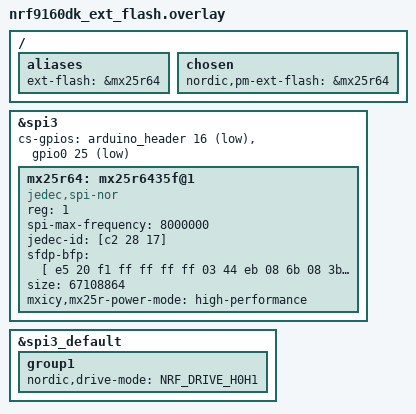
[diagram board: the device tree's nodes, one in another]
/*
 * Copyright (c) 2023 Nordic Semiconductor ASA
 *
 * SPDX-License-Identifier: LicenseRef-Nordic-5-Clause
 */

 /* The mx25r64 definition would normally be included when specifying a nrf9160dk_nrf9160_ns
  * board revision >= 0.14.0, but unfortunately twister has a bug that prevents the revision
  * overlay to get loaded when testing the sample. */
&spi3 {
	cs-gpios = <&arduino_header 16 GPIO_ACTIVE_LOW>, /* D10 */
		   <&gpio0 25 GPIO_ACTIVE_LOW>;
	mx25r64: mx25r6435f@1 {
		compatible = "jedec,spi-nor";
		reg = <1>;
		status = "okay";
		spi-max-frequency = <8000000>;
		jedec-id = [c2 28 17];
		sfdp-bfp = [
			e5 20 f1 ff  ff ff ff 03  44 eb 08 6b  08 3b 04 bb
			ee ff ff ff  ff ff 00 ff  ff ff 00 ff  0c 20 0f 52
			10 d8 00 ff  23 72 f5 00  82 ed 04 cc  44 83 68 44
			30 b0 30 b0  f7 c4 d5 5c  00 be 29 ff  f0 d0 ff ff
		];
		size = <67108864>;
		mxicy,mx25r-power-mode = "high-performance";
	};
};

/* Enable high drive mode for the SPI3 pins to get a square signal at 8 MHz */
&spi3_default {
	group1 {
		nordic,drive-mode = <NRF_DRIVE_H0H1>;
	};
};

/ {
	aliases {
		ext-flash = &mx25r64;
	};

	/* Configure partition manager to use mx25r64 as the external flash */
	chosen {
		nordic,pm-ext-flash = &mx25r64;
	};
};
